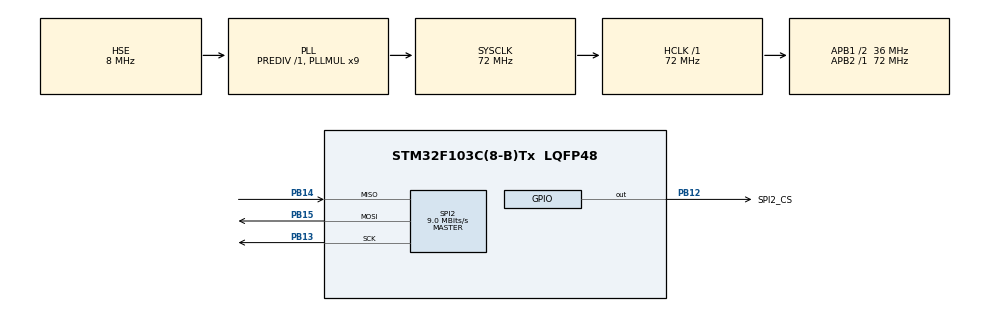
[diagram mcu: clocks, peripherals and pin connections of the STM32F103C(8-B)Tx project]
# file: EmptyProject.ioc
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FREERTOS.INCLUDE_pcTaskGetTaskName=1
FREERTOS.INCLUDE_uxTaskGetStackHighWaterMark=1
FREERTOS.INCLUDE_xTaskGetCurrentTaskHandle=1
FREERTOS.Queues01=MQTTMessQueue,16,uint16_t,0,Static,MQTTMessQueueBuffer,MQTTMessQueueControlBlock
FREERTOS.Tasks01=MainTask,24,128,StartMainTask,Default,NULL,Static,MainTaskBuffer,MainTaskControlBlock;ReadSensorsTask,8,128,StartReadSensorsTask,Default,NULL,Static,ReadSensorsTaskBuffer,ReadSensorsTaskControlBlock;MQTTTask,8,128,StartMQTTTask,Default,NULL,Static,MQTTTaskBuffer,MQTTTaskControlBlock
FREERTOS.configUSE_IDLE_HOOK=0
FREERTOS.configUSE_RECURSIVE_MUTEXES=1
FREERTOS.configUSE_TICK_HOOK=0
FREERTOS.configUSE_TIMERS=1
Mcu.Family=STM32F1
Mcu.Name=STM32F103C(8-B)Tx
Mcu.Package=LQFP48
NVIC.PriorityGroup=NVIC_PRIORITYGROUP_4
NVIC.TIM4_IRQn=true\:15\:0\:false\:false\:true\:false\:false\:true\:true
NVIC.TimeBase=TIM4_IRQn
NVIC.TimeBaseIP=TIM4
PA13.Mode=Serial_Wire
PA13.Signal=SYS_JTMS-SWDIO
PA14.Mode=Serial_Wire
PA14.Signal=SYS_JTCK-SWCLK
PB12.GPIO_Label=SPI2_CS
PB12.Signal=GPIO_Output
PB13.Mode=Full_Duplex_Master
PB13.Signal=SPI2_SCK
PB14.Mode=Full_Duplex_Master
PB14.Signal=SPI2_MISO
PB15.Mode=Full_Duplex_Master
PB15.Signal=SPI2_MOSI
PD0-OSC_IN.Mode=HSE-External-Oscillator
PD0-OSC_IN.Signal=RCC_OSC_IN
PD1-OSC_OUT.Mode=HSE-External-Oscillator
PD1-OSC_OUT.Signal=RCC_OSC_OUT
ProjectManager.HeapSize=0x200
ProjectManager.StackSize=0x400
ProjectManager.TargetToolchain=EWARM V8.32
RCC.AHBFreq_Value=72000000
RCC.APB1CLKDivider=RCC_HCLK_DIV2
RCC.APB1Freq_Value=36000000
RCC.APB1TimFreq_Value=72000000
RCC.APB2Freq_Value=72000000
RCC.APB2TimFreq_Value=72000000
RCC.HCLKFreq_Value=72000000
RCC.PLLMUL=RCC_PLL_MUL9
RCC.PLLSourceVirtual=RCC_PLLSOURCE_HSE
RCC.SYSCLKFreq_VALUE=72000000
RCC.SYSCLKSource=RCC_SYSCLKSOURCE_PLLCLK
RCC.USBFreq_Value=48000000
RCC.USBPrescaler=RCC_USBCLKSOURCE_PLL_DIV1_5
SPI2.BaudRatePrescaler=SPI_BAUDRATEPRESCALER_4
SPI2.CalculateBaudRate=9.0 MBits/s
SPI2.Direction=SPI_DIRECTION_2LINES
SPI2.Mode=SPI_MODE_MASTER
SPI2.VirtualType=VM_MASTER
VP_FREERTOS_VS_CMSIS_V2.Mode=CMSIS_V2
VP_SYS_VS_tim4.Mode=TIM4
board=TaskMaster

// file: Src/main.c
/* USER CODE BEGIN Header */
/**
  ******************************************************************************
  * @file           : main.c
  * @brief          : Main program body
  ******************************************************************************
  * @attention
  *
  * Copyright (c) 2023 STMicroelectronics.
  * All rights reserved.
  *
  * This software is licensed under terms that can be found in the LICENSE file
  * in the root directory of this software component.
  * If no LICENSE file comes with this software, it is provided AS-IS.
  *
  ******************************************************************************
  */
/* USER CODE END Header */
#include "main.h"
#include "cmsis_os.h"

/* USER CODE BEGIN Includes */
#include "GlobalDefault.h"
#include "MQTTDrive.h"
#include "BasicTasks.h"
/* USER CODE END Includes */

typedef StaticTask_t osStaticThreadDef_t;
typedef StaticQueue_t osStaticMessageQDef_t;

SPI_HandleTypeDef hspi2;

/* Definitions for MainTask */
osThreadId_t MainTaskHandle;
uint32_t MainTaskBuffer[ 128 ];
osStaticThreadDef_t MainTaskControlBlock;
const osThreadAttr_t MainTask_attributes = {
  .name = "MainTask",
  .cb_mem = &MainTaskControlBlock,
  .cb_size = sizeof(MainTaskControlBlock),
  .stack_mem = &MainTaskBuffer[0],
  .stack_size = sizeof(MainTaskBuffer),
  .priority = (osPriority_t) osPriorityNormal,
};
/* Definitions for ReadSensorsTask */
osThreadId_t ReadSensorsTaskHandle;
uint32_t ReadSensorsTaskBuffer[ 128 ];
osStaticThreadDef_t ReadSensorsTaskControlBlock;
const osThreadAttr_t ReadSensorsTask_attributes = {
  .name = "ReadSensorsTask",
  .cb_mem = &ReadSensorsTaskControlBlock,
  .cb_size = sizeof(ReadSensorsTaskControlBlock),
  .stack_mem = &ReadSensorsTaskBuffer[0],
  .stack_size = sizeof(ReadSensorsTaskBuffer),
  .priority = (osPriority_t) osPriorityLow,
};
/* Definitions for MQTTTask */
osThreadId_t MQTTTaskHandle;
uint32_t MQTTTaskBuffer[ 128 ];
osStaticThreadDef_t MQTTTaskControlBlock;
const osThreadAttr_t MQTTTask_attributes = {
  .name = "MQTTTask",
  .cb_mem = &MQTTTaskControlBlock,
  .cb_size = sizeof(MQTTTaskControlBlock),
  .stack_mem = &MQTTTaskBuffer[0],
  .stack_size = sizeof(MQTTTaskBuffer),
  .priority = (osPriority_t) osPriorityLow,
};
/* Definitions for MQTTMessQueue */
osMessageQueueId_t MQTTMessQueueHandle;
uint8_t MQTTMessQueueBuffer[ 16 * sizeof( uint16_t ) ];
osStaticMessageQDef_t MQTTMessQueueControlBlock;
const osMessageQueueAttr_t MQTTMessQueue_attributes = {
  .name = "MQTTMessQueue",
  .cb_mem = &MQTTMessQueueControlBlock,
  .cb_size = sizeof(MQTTMessQueueControlBlock),
  .mq_mem = &MQTTMessQueueBuffer,
  .mq_size = sizeof(MQTTMessQueueBuffer)
};

void SystemClock_Config(void);
static void MX_GPIO_Init(void);
static void MX_SPI2_Init(void);
void StartMainTask(void *argument);
void StartReadSensorsTask(void *argument);
void StartMQTTTask(void *argument);

int main(void)
{

  /* MCU Configuration--------------------------------------------------------*/

  /* Reset of all peripherals, Initializes the Flash interface and the Systick. */
  HAL_Init();

  /* Configure the system clock */
  SystemClock_Config();

  /* Initialize all configured peripherals */
  MX_GPIO_Init();
  MX_SPI2_Init();

  /* Init scheduler */
  osKernelInitialize();

  /* Create the queue(s) */
  /* creation of MQTTMessQueue */
  MQTTMessQueueHandle = osMessageQueueNew (16, sizeof(uint16_t), &MQTTMessQueue_attributes);

  /* Create the thread(s) */
  /* creation of MainTask */
  MainTaskHandle = osThreadNew(StartMainTask, NULL, &MainTask_attributes);

  /* creation of ReadSensorsTask */
  ReadSensorsTaskHandle = osThreadNew(StartReadSensorsTask, NULL, &ReadSensorsTask_attributes);

  /* creation of MQTTTask */
  MQTTTaskHandle = osThreadNew(StartMQTTTask, NULL, &MQTTTask_attributes);

  /* Start scheduler */
  osKernelStart();
  /* We should never get here as control is now taken by the scheduler */
  /* Infinite loop */
	while (1)
	{

	}
}

void SystemClock_Config(void)
{
  RCC_OscInitTypeDef RCC_OscInitStruct = {0};
  RCC_ClkInitTypeDef RCC_ClkInitStruct = {0};

  /** Initializes the RCC Oscillators according to the specified parameters
  * in the RCC_OscInitTypeDef structure.
  */
  RCC_OscInitStruct.OscillatorType = RCC_OSCILLATORTYPE_HSE;
  RCC_OscInitStruct.HSEState = RCC_HSE_ON;
  RCC_OscInitStruct.HSEPredivValue = RCC_HSE_PREDIV_DIV1;
  RCC_OscInitStruct.HSIState = RCC_HSI_ON;
  RCC_OscInitStruct.PLL.PLLState = RCC_PLL_ON;
  RCC_OscInitStruct.PLL.PLLSource = RCC_PLLSOURCE_HSE;
  RCC_OscInitStruct.PLL.PLLMUL = RCC_PLL_MUL9;
  if (HAL_RCC_OscConfig(&RCC_OscInitStruct) != HAL_OK)
  {
    Error_Handler();
  }

  /** Initializes the CPU, AHB and APB buses clocks
  */
  RCC_ClkInitStruct.ClockType = RCC_CLOCKTYPE_HCLK|RCC_CLOCKTYPE_SYSCLK
                              |RCC_CLOCKTYPE_PCLK1|RCC_CLOCKTYPE_PCLK2;
  RCC_ClkInitStruct.SYSCLKSource = RCC_SYSCLKSOURCE_PLLCLK;
  RCC_ClkInitStruct.AHBCLKDivider = RCC_SYSCLK_DIV1;
  RCC_ClkInitStruct.APB1CLKDivider = RCC_HCLK_DIV2;
  RCC_ClkInitStruct.APB2CLKDivider = RCC_HCLK_DIV1;

  if (HAL_RCC_ClockConfig(&RCC_ClkInitStruct, FLASH_LATENCY_2) != HAL_OK)
  {
    Error_Handler();
  }
}

static void MX_SPI2_Init(void)
{

  /* SPI2 parameter configuration*/
  hspi2.Instance = SPI2;
  hspi2.Init.Mode = SPI_MODE_MASTER;
  hspi2.Init.Direction = SPI_DIRECTION_2LINES;
  hspi2.Init.DataSize = SPI_DATASIZE_8BIT;
  hspi2.Init.CLKPolarity = SPI_POLARITY_LOW;
  hspi2.Init.CLKPhase = SPI_PHASE_1EDGE;
  hspi2.Init.NSS = SPI_NSS_SOFT;
  hspi2.Init.BaudRatePrescaler = SPI_BAUDRATEPRESCALER_4;
  hspi2.Init.FirstBit = SPI_FIRSTBIT_MSB;
  hspi2.Init.TIMode = SPI_TIMODE_DISABLE;
  hspi2.Init.CRCCalculation = SPI_CRCCALCULATION_DISABLE;
  hspi2.Init.CRCPolynomial = 10;
  if (HAL_SPI_Init(&hspi2) != HAL_OK)
  {
    Error_Handler();
  }

}

static void MX_GPIO_Init(void)
{
  GPIO_InitTypeDef GPIO_InitStruct = {0};

  /* GPIO Ports Clock Enable */
  __HAL_RCC_GPIOD_CLK_ENABLE();
  __HAL_RCC_GPIOB_CLK_ENABLE();
  __HAL_RCC_GPIOA_CLK_ENABLE();

  /*Configure GPIO pin Output Level */
  HAL_GPIO_WritePin(SPI2_CS_GPIO_Port, SPI2_CS_Pin, GPIO_PIN_RESET);

  /*Configure GPIO pin : SPI2_CS_Pin */
  GPIO_InitStruct.Pin = SPI2_CS_Pin;
  GPIO_InitStruct.Mode = GPIO_MODE_OUTPUT_PP;
  GPIO_InitStruct.Pull = GPIO_NOPULL;
  GPIO_InitStruct.Speed = GPIO_SPEED_FREQ_LOW;
  HAL_GPIO_Init(SPI2_CS_GPIO_Port, &GPIO_InitStruct);

}

void StartMainTask(void *argument)
{
  /* USER CODE BEGIN 5 */
	Initialisation();

	/* Infinite loop */
	for (;;)
	{

		osDelay(1);
	}
  /* USER CODE END 5 */
}

void StartReadSensorsTask(void *argument)
{
	for (;;)
	{
		osDelay(1);
	}
}

void StartMQTTTask(void *argument)
{
  /* USER CODE BEGIN StartMQTTTask */
	/* Infinite loop */
	for (;;)
	{
		MQTTDriver();
		osDelay(1);
	}
  /* USER CODE END StartMQTTTask */
}

void HAL_TIM_PeriodElapsedCallback(TIM_HandleTypeDef *htim)
{
  if (htim->Instance == TIM4) {
    HAL_IncTick();
  }
}

void Error_Handler(void)
{
	__disable_irq();
	while (1)
	{
	}
}
